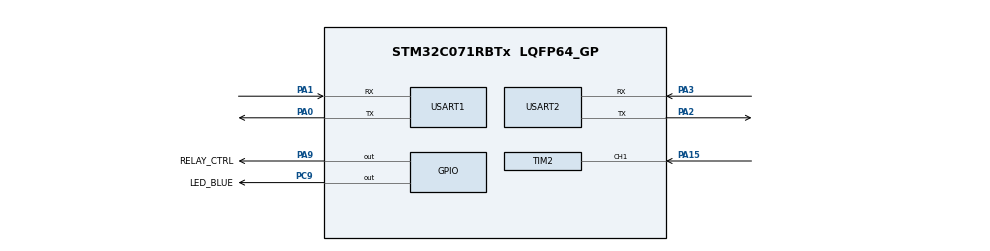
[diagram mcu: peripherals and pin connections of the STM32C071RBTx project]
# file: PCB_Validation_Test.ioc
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Mcu.Family=STM32C0
Mcu.Name=STM32C071RBTx
Mcu.Package=LQFP64_GP
NVIC.USART1_IRQn=true\:0\:0\:false\:false\:true\:true\:true\:true
NVIC.USART2_IRQn=true\:0\:0\:false\:false\:true\:true\:true\:true
PA0.Mode=Asynchronous
PA0.Signal=USART1_TX
PA1.Mode=Asynchronous
PA1.Signal=USART1_RX
PA15.Signal=S_TIM2_CH1
PA2.Mode=Asynchronous
PA2.Signal=USART2_TX
PA3.Mode=Asynchronous
PA3.Signal=USART2_RX
PA9.GPIO_Label=RELAY_CTRL
PA9.Signal=GPIO_Output
PC9.GPIO_Label=LED_BLUE
PC9.Signal=GPIO_Output
ProjectManager.HeapSize=0x200
ProjectManager.StackSize=0x400
ProjectManager.TargetToolchain=MDK-ARM V5.39
RCC.ADCFreq_Value=12000000
RCC.AHBFreq_Value=12000000
RCC.CortexFreq_Value=12000000
RCC.EXTERNAL_CLOCK_VALUE=12288000
RCC.HCLKFreq_Value=12000000
RCC.HSE_VALUE=8000000
RCC.HSI48_VALUE=48000000
RCC.HSI_VALUE=48000000
RCC.LSE_VALUE=32768
RCC.SYSCLKFreq_VALUE=12000000
SH.S_TIM2_CH1.0=TIM2_CH1,TriggerSource_TI1FP1
USART1.VirtualMode-Asynchronous=VM_ASYNC
USART2.VirtualMode-Asynchronous=VM_ASYNC
VP_TIM2_VS_ControllerModeClock.Mode=Clock Mode
board=NUCLEO-C071RB

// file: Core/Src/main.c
/* USER CODE BEGIN Header */
/**
  ******************************************************************************
  * @file           : main.c
  * @brief          : Main program body
  ******************************************************************************
  * @attention
  *
  * Copyright (c) 2025 STMicroelectronics.
  * All rights reserved.
  *
  * This software is licensed under terms that can be found in the LICENSE file
  * in the root directory of this software component.
  * If no LICENSE file comes with this software, it is provided AS-IS.
  *
  ******************************************************************************
  */
/* USER CODE END Header */
#include "main.h"
#include "usart.h"
#include "gpio.h"
#include "tim.h"

/* USER CODE BEGIN Includes */
#include <stdio.h>
#include "cli.h"
#include "pcb_frequency.h"
/* USER CODE END Includes */

void SystemClock_Config(void);
void DWIN_SendData(uint16_t vp_address, int32_t value);

/* USER CODE BEGIN 0 */
#define PUTCHAR_PROTOTYPE int fputc(int ch, FILE *f)

PUTCHAR_PROTOTYPE
{
  // A chamada aqui é a mesma do nosso teste que funcionou!
  HAL_UART_Transmit(&huart2, (uint8_t *)&ch, 1, HAL_MAX_DELAY);
  return ch;
}
/* USER CODE END 0 */
void DWIN_SendData(uint16_t vp_address, int32_t value)
{
    uint8_t dwin_frame[10];
    dwin_frame[0] = 0x5A; dwin_frame[1] = 0xA5; dwin_frame[2] = 0x07;
    dwin_frame[3] = 0x82; dwin_frame[4] = (uint8_t)(vp_address >> 8);
    dwin_frame[5] = (uint8_t)(vp_address); dwin_frame[6] = (uint8_t)(value >> 24);
    dwin_frame[7] = (uint8_t)(value >> 16); dwin_frame[8] = (uint8_t)(value >> 8);
    dwin_frame[9] = (uint8_t)(value);
    HAL_UART_Transmit(&huart1, dwin_frame, 10, 100);
}
int main(void)
{

  /* MCU Configuration--------------------------------------------------------*/

  /* Reset of all peripherals, Initializes the Flash interface and the Systick. */
  HAL_Init();

  /* Configure the system clock */
  SystemClock_Config();

  /* Initialize all configured peripherals */
  MX_GPIO_Init();
  MX_USART2_UART_Init();
	MX_USART1_UART_Init();
	MX_TIM2_Init();
  /* USER CODE BEGIN 2 */
	CLI_Init();
	Frequency_Init();
  /* USER CODE END 2 */

  /* Infinite loop */
  while (1)
  {
		//CLI_Process();

		Frequency_Reset();

    // Aguarda a janela de tempo de 1 segundo
    HAL_Delay(1000);
    uint32_t freq_atual = Frequency_Get_Pulse_Count(); //Contador de 32Bit conta ate +- 4 Bi muito além dos 3 Mi do oscilador

    // --- LINHAS DE DEPURAÇÃO ---
    int32_t valor_para_display = (int32_t)(freq_atual / 1000);
    printf("Debug: Freq = %u Hz, Valor Enviado = %d\r\n", (unsigned int)freq_atual, (int)valor_para_display);
    // --- FIM DAS LINHAS DE DEPURAÇÃO ---

    DWIN_SendData(0x1050, valor_para_display);

  }
}

void SystemClock_Config(void)
{
  RCC_OscInitTypeDef RCC_OscInitStruct = {0};
  RCC_ClkInitTypeDef RCC_ClkInitStruct = {0};

  __HAL_FLASH_SET_LATENCY(FLASH_LATENCY_0);

  /** Initializes the RCC Oscillators according to the specified parameters
  * in the RCC_OscInitTypeDef structure.
  */
  RCC_OscInitStruct.OscillatorType = RCC_OSCILLATORTYPE_HSI;
  RCC_OscInitStruct.HSIState = RCC_HSI_ON;
  RCC_OscInitStruct.HSIDiv = RCC_HSI_DIV4;
  RCC_OscInitStruct.HSICalibrationValue = RCC_HSICALIBRATION_DEFAULT;
  if (HAL_RCC_OscConfig(&RCC_OscInitStruct) != HAL_OK)
  {
    Error_Handler();
  }

  /** Initializes the CPU, AHB and APB buses clocks
  */
  RCC_ClkInitStruct.ClockType = RCC_CLOCKTYPE_HCLK|RCC_CLOCKTYPE_SYSCLK
                              |RCC_CLOCKTYPE_PCLK1;
  RCC_ClkInitStruct.SYSCLKSource = RCC_SYSCLKSOURCE_HSI;
  RCC_ClkInitStruct.SYSCLKDivider = RCC_SYSCLK_DIV1;
  RCC_ClkInitStruct.AHBCLKDivider = RCC_HCLK_DIV1;
  RCC_ClkInitStruct.APB1CLKDivider = RCC_APB1_DIV1;

  if (HAL_RCC_ClockConfig(&RCC_ClkInitStruct, FLASH_LATENCY_0) != HAL_OK)
  {
    Error_Handler();
  }
}

void Error_Handler(void)
{
  __disable_irq();
  while (1)
  {
  }
}
